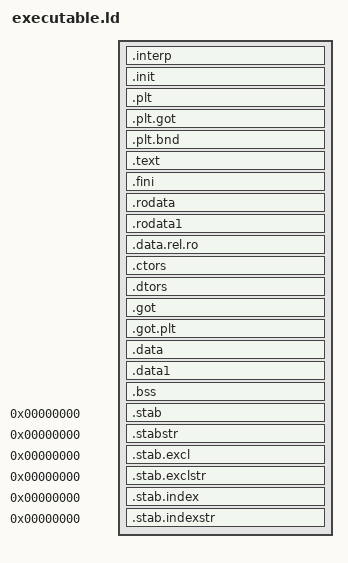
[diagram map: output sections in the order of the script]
/* Copyright (C) 2014-2016 Free Software Foundation, Inc.
   Copying and distribution of this script, with or without modification,
   are permitted in any medium without royalty provided the copyright
   notice and this notice are preserved.  */

OUTPUT_FORMAT("elf64-x86-64", "elf64-x86-64",
	      "elf64-x86-64")
OUTPUT_ARCH(i386:x86-64)
ENTRY(_start)
SEARCH_DIR("../bin/root/lib");

PHDRS
{
  text PT_LOAD FILEHDR PHDRS ;
  data PT_LOAD ;
}

SECTIONS
{
  /* Read-only sections, merged into text segment: */
  PROVIDE (__executable_start = SEGMENT_START("text-segment", 0x200000));
  . = SEGMENT_START("text-segment", 0x200000) + SIZEOF_HEADERS;
  .interp         : { *(.interp) } :text
  .init           :
  {
    KEEP (*(SORT_NONE(.init)))
  }
  .plt            : { *(.plt) *(.iplt) }
.plt.got        : { *(.plt.got) }
.plt.bnd        : { *(.plt.bnd) }
  .text         :
  {
    *(.text.unlikely .text.*_unlikely .text.unlikely.*)
    *(.text.exit .text.exit.*)
    *(.text.startup .text.startup.*)
    *(.text.hot .text.hot.*)
    *(.text .stub .text.* .gnu.linkonce.t.*)
    /* .gnu.warning sections are handled specially by elf32.em.  */
    *(.gnu.warning)
  }
  .fini           :
  {
    KEEP (*(SORT_NONE(.fini)))
  }
  PROVIDE (__etext = .);
  PROVIDE (_etext = .);
  PROVIDE (etext = .);
  .rodata         : { *(.rodata .rodata.* .gnu.linkonce.r.*) }
  .rodata1        : { *(.rodata1) }
  . = ALIGN(4096);
  . = SEGMENT_START("data-segment", .);
/*  . = DATA_SEGMENT_ALIGN (CONSTANT (MAXPAGESIZE), CONSTANT (COMMONPAGESIZE)); */
  .data.rel.ro : { *(.data.rel.ro.local* .gnu.linkonce.d.rel.ro.local.*) *(.data.rel.ro .data.rel.ro.* .gnu.linkonce.d.rel.ro.*) } :data
  .ctors          :
  {
    /* gcc uses crtbegin.o to find the start of
       the constructors, so we make sure it is
       first.  Because this is a wildcard, it
       doesn't matter if the user does not
       actually link against crtbegin.o; the
       linker won't look for a file to match a
       wildcard.  The wildcard also means that it
       doesn't matter which directory crtbegin.o
       is in.  */
    KEEP (*crtbegin.o(.ctors))
    KEEP (*crtbegin?.o(.ctors))
    /* We don't want to include the .ctor section from
       the crtend.o file until after the sorted ctors.
       The .ctor section from the crtend file contains the
       end of ctors marker and it must be last */
    KEEP (*(EXCLUDE_FILE (*crtend.o *crtend?.o ) .ctors))
    KEEP (*(SORT(.ctors.*)))
    KEEP (*(.ctors))
  }
  .dtors          :
  {
    KEEP (*crtbegin.o(.dtors))
    KEEP (*crtbegin?.o(.dtors))
    KEEP (*(EXCLUDE_FILE (*crtend.o *crtend?.o ) .dtors))
    KEEP (*(SORT(.dtors.*)))
    KEEP (*(.dtors))
  }
  .got            : { *(.got) *(.igot) }
/*  . = DATA_SEGMENT_RELRO_END (SIZEOF (.got.plt) >= 24 ? 24 : 0, .); */
  .got.plt        : { *(.got.plt)  *(.igot.plt) }
  .data           :
  {
    *(.data .data.* .gnu.linkonce.d.*)
    SORT(CONSTRUCTORS)
  }
  .data1          : { *(.data1) }
  _edata = .; PROVIDE (edata = .);
  __bss_start = 0x0000001000000000;
  .bss            :
  {
   *(.dynbss)
   *(.bss .bss.* .gnu.linkonce.b.*)
   *(COMMON)
   /* Align here to ensure that the .bss section occupies space up to
      _end.  Align after .bss to ensure correct alignment even if the
      .bss section disappears because there are no input sections.
      FIXME: Why do we need it? When there is no .bss section, we don't
      pad the .data section.  */
   . = ALIGN(. != 0 ? 64 / 8 : 1);
  }
  . = ALIGN(64 / 8);
  _end = .; PROVIDE (end = .);
/*  . = DATA_SEGMENT_END (.); */
  /* Stabs debugging sections.  */
  .stab          0 : { *(.stab) }
  .stabstr       0 : { *(.stabstr) }
  .stab.excl     0 : { *(.stab.excl) }
  .stab.exclstr  0 : { *(.stab.exclstr) }
  .stab.index    0 : { *(.stab.index) }
  .stab.indexstr 0 : { *(.stab.indexstr) }
  /DISCARD/ : { *(.note.*) *(.comment*) *(.gnu_debuglink) *(.gnu.*) *(.eh*) }
}

